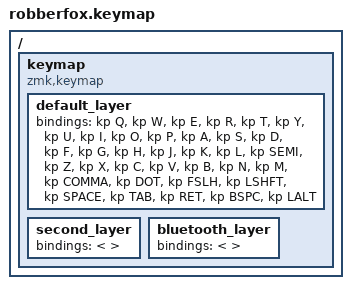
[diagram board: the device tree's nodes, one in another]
#include <behaviors.dtsi>
#include <dt-bindings/zmk/keys.h>
#include <dt-bindings/zmk/bt.h>

/ {
    keymap {
        compatible = "zmk,keymap";

        default_layer {
            bindings = <
                &kp Q &kp W &kp E &kp R &kp T   &kp Y &kp U &kp I &kp O &kp P
                &kp A &kp S &kp D &kp F &kp G   &kp H &kp J &kp K &kp L &kp SEMI
                &kp Z &kp X &kp C &kp V &kp B   &kp N &kp M &kp COMMA &kp DOT &kp FSLH
                &kp LSHFT &kp SPACE &kp TAB     &kp RET &kp BSPC &kp LALT
            >;
        };
		second_layer {
			bindings = <
			>;
		};
		bluetooth_layer {
			bindings = <
			>;
		};
    };
};
